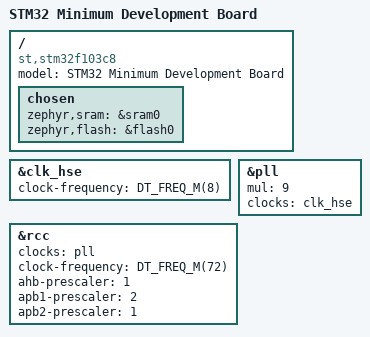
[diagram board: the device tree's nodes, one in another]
/*
 * Copyright (c) 2017, embedjournal.com
 *
 * SPDX-License-Identifier: Apache-2.0
 */

/dts-v1/;
/*
 * Copyright (c) 2019, embedjournal.com
 *
 * SPDX-License-Identifier: Apache-2.0
 */

/dts-v1/;
#include <st/f1/stm32f103X8.dtsi>
#include <st/f1/stm32f103r(8-b)tx-pinctrl.dtsi>

/ {
	model = "STM32 Minimum Development Board";
	compatible = "st,stm32f103c8";

	chosen {
		zephyr,sram = &sram0;
		zephyr,flash = &flash0;
	};
};

&clk_hse {
	clock-frequency = <DT_FREQ_M(8)>;
	status = "okay";
};

&pll {
	mul = <9>;
	clocks = <&clk_hse>;
	status = "okay";
};

&rcc {
	clocks = <&pll>;
	clock-frequency = <DT_FREQ_M(72)>;
	ahb-prescaler = <1>;
	apb1-prescaler = <2>;
	apb2-prescaler = <1>;
};
